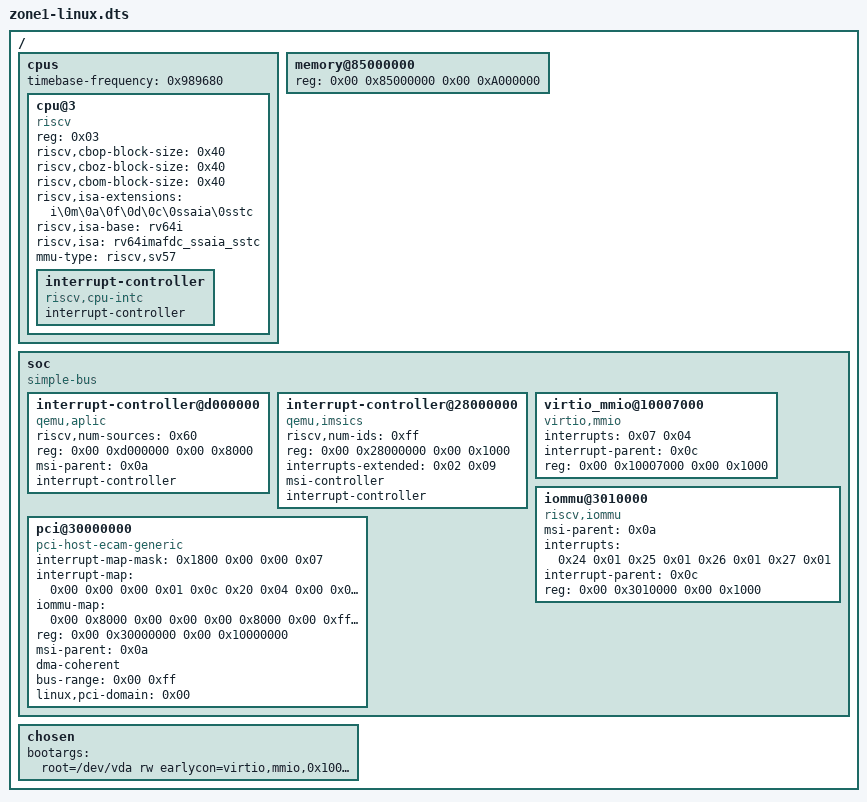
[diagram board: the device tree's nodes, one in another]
/dts-v1/;

/ {
	#address-cells = <0x02>;
	#size-cells = <0x02>;

	cpus {
		#address-cells = <0x01>;
		#size-cells = <0x00>;
		timebase-frequency = <0x989680>;

		cpu@3 {
			phandle = <0x01>;
			device_type = "cpu";
			reg = <0x03>;
			status = "okay";
			compatible = "riscv";
			riscv,cbop-block-size = <0x40>;
			riscv,cboz-block-size = <0x40>;
			riscv,cbom-block-size = <0x40>;
			riscv,isa-extensions = "i\0m\0a\0f\0d\0c\0ssaia\0sstc";
			riscv,isa-base = "rv64i";
			riscv,isa = "rv64imafdc_ssaia_sstc";
			mmu-type = "riscv,sv57";

			interrupt-controller {
				#interrupt-cells = <0x01>;
				interrupt-controller;
				compatible = "riscv,cpu-intc";
				phandle = <0x02>;
			};
		};
	};

	memory@85000000 {
		device_type = "memory";
		reg = <0x00 0x85000000 0x00 0xA000000>;
	};

	soc {
		#address-cells = <0x02>;
		#size-cells = <0x02>;
		compatible = "simple-bus";
		ranges;

		interrupt-controller@d000000 {
			phandle = <0x0c>;
			riscv,num-sources = <0x60>;
			reg = <0x00 0xd000000 0x00 0x8000>;
			msi-parent = <0x0a>;
			interrupt-controller;
			#interrupt-cells = <0x02>;
			#address-cells = <0x00>;
			compatible = "qemu,aplic\0riscv,aplic";
		};

		interrupt-controller@28000000 {
			phandle = <0x0a>;
			riscv,num-ids = <0xff>;
			reg = <0x00 0x28000000 0x00 0x1000>;	// S-mode interrupt-files
			interrupts-extended = <0x02 0x09>;
			msi-controller;
			interrupt-controller;
			#interrupt-cells = <0x00>;
			compatible = "qemu,imsics\0riscv,imsics";
		};

		virtio_mmio@10007000 {
			interrupts = <0x07 0x04>;
			interrupt-parent = <0x0c>;
			reg = <0x00 0x10007000 0x00 0x1000>;
			compatible = "virtio,mmio";
		};

		iommu@3010000 {
			msi-parent = <0x0a>;
			interrupts = <0x24 0x01 0x25 0x01 0x26 0x01 0x27 0x01>;
			interrupt-parent = <0x0c>;
			reg = <0x00 0x3010000 0x00 0x1000>;
			phandle = <0x8000>;
			#iommu-cells = <0x01>;
			compatible = "riscv,iommu";
		};

		pci@30000000 {
			interrupt-map-mask = <0x1800 0x00 0x00 0x07>;
			interrupt-map = <0x00 0x00 0x00 0x01 0x0c 0x20 0x04 0x00 0x00 0x00 0x02 0x0c 0x21 0x04 0x00 0x00 0x00 0x03 0x0c 0x22 0x04 0x00 0x00 0x00 0x04 0x0c 0x23 0x04 0x800 0x00 0x00 0x01 0x0c 0x21 0x04 0x800 0x00 0x00 0x02 0x0c 0x22 0x04 0x800 0x00 0x00 0x03 0x0c 0x23 0x04 0x800 0x00 0x00 0x04 0x0c 0x20 0x04 0x1000 0x00 0x00 0x01 0x0c 0x22 0x04 0x1000 0x00 0x00 0x02 0x0c 0x23 0x04 0x1000 0x00 0x00 0x03 0x0c 0x20 0x04 0x1000 0x00 0x00 0x04 0x0c 0x21 0x04 0x1800 0x00 0x00 0x01 0x0c 0x23 0x04 0x1800 0x00 0x00 0x02 0x0c 0x20 0x04 0x1800 0x00 0x00 0x03 0x0c 0x21 0x04 0x1800 0x00 0x00 0x04 0x0c 0x22 0x04>;
			iommu-map = <0x00 0x8000 0x00 0x00 0x00 0x8000 0x00 0xffff>;
			ranges = <0x1000000 0x00 0x00 0x00 0x3000000 0x00 0x10000 0x2000000 0x00 0x40000000 0x00 0x40000000 0x00 0x40000000 0x3000000 0x04 0x00 0x04 0x00 0x04 0x00>;
			reg = <0x00 0x30000000 0x00 0x10000000>;
			msi-parent = <0x0a>;
			dma-coherent;
			bus-range = <0x00 0xff>;
			linux,pci-domain = <0x00>;
			device_type = "pci";
			compatible = "pci-host-ecam-generic";
			#size-cells = <0x02>;
			#interrupt-cells = <0x01>;
			#address-cells = <0x03>;
		};
	};

	chosen {
		bootargs = "root=/dev/vda rw earlycon=virtio,mmio,0x10007000 console=hvc0";
	};
};
